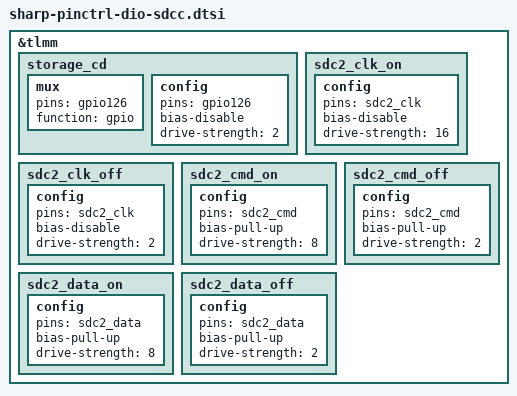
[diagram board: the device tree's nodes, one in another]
/* Copyright (c) 2016-2017, The Linux Foundation. All rights reserved.
 *
 * This program is free software; you can redistribute it and/or modify
 * it under the terms of the GNU General Public License version 2 and
 * only version 2 as published by the Free Software Foundation.
 *
 * This program is distributed in the hope that it will be useful,
 * but WITHOUT ANY WARRANTY; without even the implied warranty of
 * MERCHANTABILITY or FITNESS FOR A PARTICULAR PURPOSE.  See the
 * GNU General Public License for more details.
 */

&tlmm {
	storage_cd: storage_cd {
		mux {
			pins = "gpio126";
			function = "gpio";
		};

		config {
			pins = "gpio126";
			bias-disable;       /* non pull */
			drive-strength = <2>;   /* 2 MA */
		};
	};

	sdc2_clk_on: sdc2_clk_on {
		config {
			pins = "sdc2_clk";
			bias-disable;		/* NO pull */
			drive-strength = <16>;	/* 16 MA */
		};
	};

	sdc2_clk_off: sdc2_clk_off {
		config {
			pins = "sdc2_clk";
			bias-disable;		/* NO pull */
			drive-strength = <2>;	/* 2 MA */
		};
	};

	sdc2_cmd_on: sdc2_cmd_on {
		config {
			pins = "sdc2_cmd";
			bias-pull-up;		/* pull up */
			drive-strength = <8>;	/* 8 MA */
		};
	};

	sdc2_cmd_off: sdc2_cmd_off {
		config {
			pins = "sdc2_cmd";
			bias-pull-up;		/* pull up */
			drive-strength = <2>;	/* 2 MA */
		};
	};

	sdc2_data_on: sdc2_data_on {
		config {
			pins = "sdc2_data";
			bias-pull-up;		/* pull up */
			drive-strength = <8>;	/* 8 MA */
		};
	};

	sdc2_data_off: sdc2_data_off {
		config {
			pins = "sdc2_data";
			bias-pull-up;		/* pull up */
			drive-strength = <2>;	/* 2 MA */
		};
	};
};

